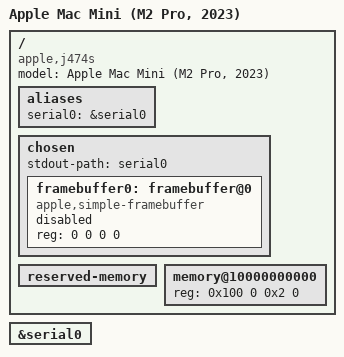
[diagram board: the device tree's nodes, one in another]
// SPDX-License-Identifier: GPL-2.0+ OR MIT
/*
 * Mac Mini (M2 Pro, 2023)
 *
 * target-type: J474s
 *
 * Copyright The Asahi Linux Contributors
 */

/dts-v1/;

#include "t6020.dtsi"

/ {
	compatible = "apple,j474s", "apple,t6020", "apple,arm-platform";
	model = "Apple Mac Mini (M2 Pro, 2023)";

	aliases {
		serial0 = &serial0;
	};

	chosen {
		#address-cells = <2>;
		#size-cells = <2>;
		ranges;

		stdout-path = "serial0";

		framebuffer0: framebuffer@0 {
			compatible = "apple,simple-framebuffer", "simple-framebuffer";
			reg = <0 0 0 0>; /* to be filled by loader */
			status = "disabled";
		};
	};

	reserved-memory {
		#address-cells = <2>;
		#size-cells = <2>;
		ranges;
		/* to be filled by loader */
	};

	memory@10000000000 {
		device_type = "memory";
		reg = <0x100 0 0x2 0>; /* to be filled by loader */
	};
};

&serial0 {
	status = "okay";
};

